VERSION ""

NS_ :

BS_:

BU_: NOONE SENSOR MASTER MOTOR GPS ANDROID

BO_ 100 MASTER_HEARTBEAT: 1 MASTER
 SG_ MASTER_HEARTBEAT_cmd : 0|8@1+ (1,0) [0|0] "" SENSOR,MOTOR

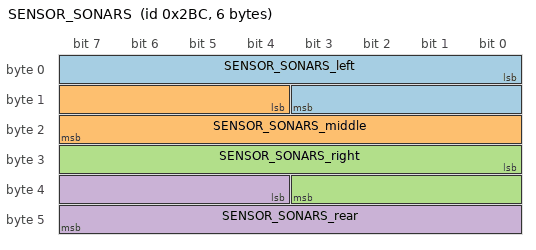
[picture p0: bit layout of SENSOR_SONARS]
BO_ 700 SENSOR_SONARS: 6 SENSOR
 SG_ SENSOR_SONARS_left : 0|12@1+ (0.1,0) [0|0] "" MASTER
 SG_ SENSOR_SONARS_middle : 12|12@1+ (0.1,0) [0|0] "" MASTER
 SG_ SENSOR_SONARS_right : 24|12@1+ (0.1,0) [0|0] "" MASTER
 SG_ SENSOR_SONARS_rear : 36|12@1+ (0.1,0) [0|0] "" MASTER

BO_ 704 MOTOR_CMD: 1 MASTER
 SG_ MOTOR_CMD_steer : 0|8@1+ (1,0) [10|20] "" MOTOR
 SG_ MOTOR_CMD_drive : 8|8@1+ (1,0) [10|20] "" MOTOR

BO_ 706 GPS_INFO_COORDINATES: 1 GPS
 SG_ GPS_INFO_COORDINATES_x : 0|32@1+ (1,0) [0|0] "" MASTER
 SG_ GPS_INFO_COORDINATES_y : 33|63@1+ (1,0) [0|0] "" MASTER

BO_ 708 GPS_INFO_HEADING: 1 GPS
 SG_ GPS_INFO_HEADING : 0|8@1+ (1,0) [0|0] "" MASTER

CM_ BU_ NOONE "No node, used to indicate if it's a debug message going to no one";
CM_ BU_ MASTER "The driver controller driving the car";
CM_ BU_ SENSOR "The sensor controller of the car";
CM_ BU_ MOTOR "The motor controller of the car";
CM_ BO_ 100 "Sync message used to synchronize the controllers";

BA_DEF_  "BusType" STRING ;
BA_DEF_ SG_ "FieldType" STRING ;
BA_DEF_ BO_ "GenMsgCycleTime" INT 0 0;

BA_DEF_DEF_ "BusType" "CAN";
BA_DEF_DEF_ "FieldType" "";

BA_ "GenMsgCycleTime" BO_ 100 1000;
BA_ "GenMsgCycleTime" BO_ 200 100;
BA_ "GenMsgCycleTime" BO_ 300 100;
BA_ "FieldType" SG_ 100 MASTER_HEARTBEAT_cmd "MASTER_HEARTBEAT_cmd"
BA_ "FieldType" SG_ 704 MOTOR_CMD_drive "MOTOR_CMD_drive"
BA_ "FieldType" SG_ 704 MOTOR_CMD_steer "MOTOR_CMD_steer"

VAL_ 100 MASTER_HEARTBEAT_cmd 0 "DRIVER_HEARTBEAT_cmd_NOOP" 1 "DRIVER_HEARTBEAT_cmd_SYNC" 2 "DRIVER_HEARTBEAT_cmd_REBOOT" ;
VAL_ 700 MOTOR_CMD_drive 4 "MOTOR_CMD_drive_fast" 3 "MOTOR_CMD_drive_medium" 2 "MOTOR_CMD_drive_slow" 1 "MOTOR_CMD_drive_reverse" 0 "MOTOR_CMD_drive_stop" ;
VAL_ 700 MOTOR_CMD_steer 2 "MOTOR_CMD_steer_right" 1 "MOTOR_CMD_steer_straight" 0 "MOTOR_CMD_steer_left" ;
